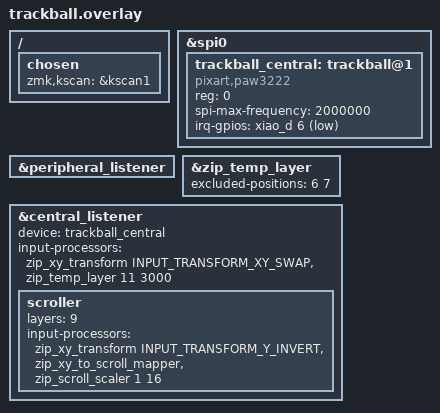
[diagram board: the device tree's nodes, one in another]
/ {
    chosen {
        zmk,kscan = &kscan1;
    };
};

&spi0 {
    status = "okay";

    trackball_central: trackball@1 {
        status = "okay";
        compatible = "pixart,paw3222";
        reg = <0>;
        spi-max-frequency = <2000000>;
        irq-gpios = <&xiao_d 6 (GPIO_ACTIVE_LOW | GPIO_PULL_UP)>;
    };
};

// ペリフェラル（split経由）のリスナーを有効化
&peripheral_listener {
    status = "okay";
};

// セントラルのリスナーを有効化し、deviceを紐付け
&zip_temp_layer {
    excluded-positions = <6 7>;
};

&central_listener {
    status = "okay";
    device = <&trackball_central>;
    input-processors = 
        <&zip_xy_transform INPUT_TRANSFORM_XY_SWAP>,
        <&zip_temp_layer 11 3000>;

    scroller {
        layers = <9>;
        input-processors = 
            <&zip_xy_transform INPUT_TRANSFORM_Y_INVERT>,
            <&zip_xy_to_scroll_mapper>,
            <&zip_scroll_scaler 1 16>;
    };
};
